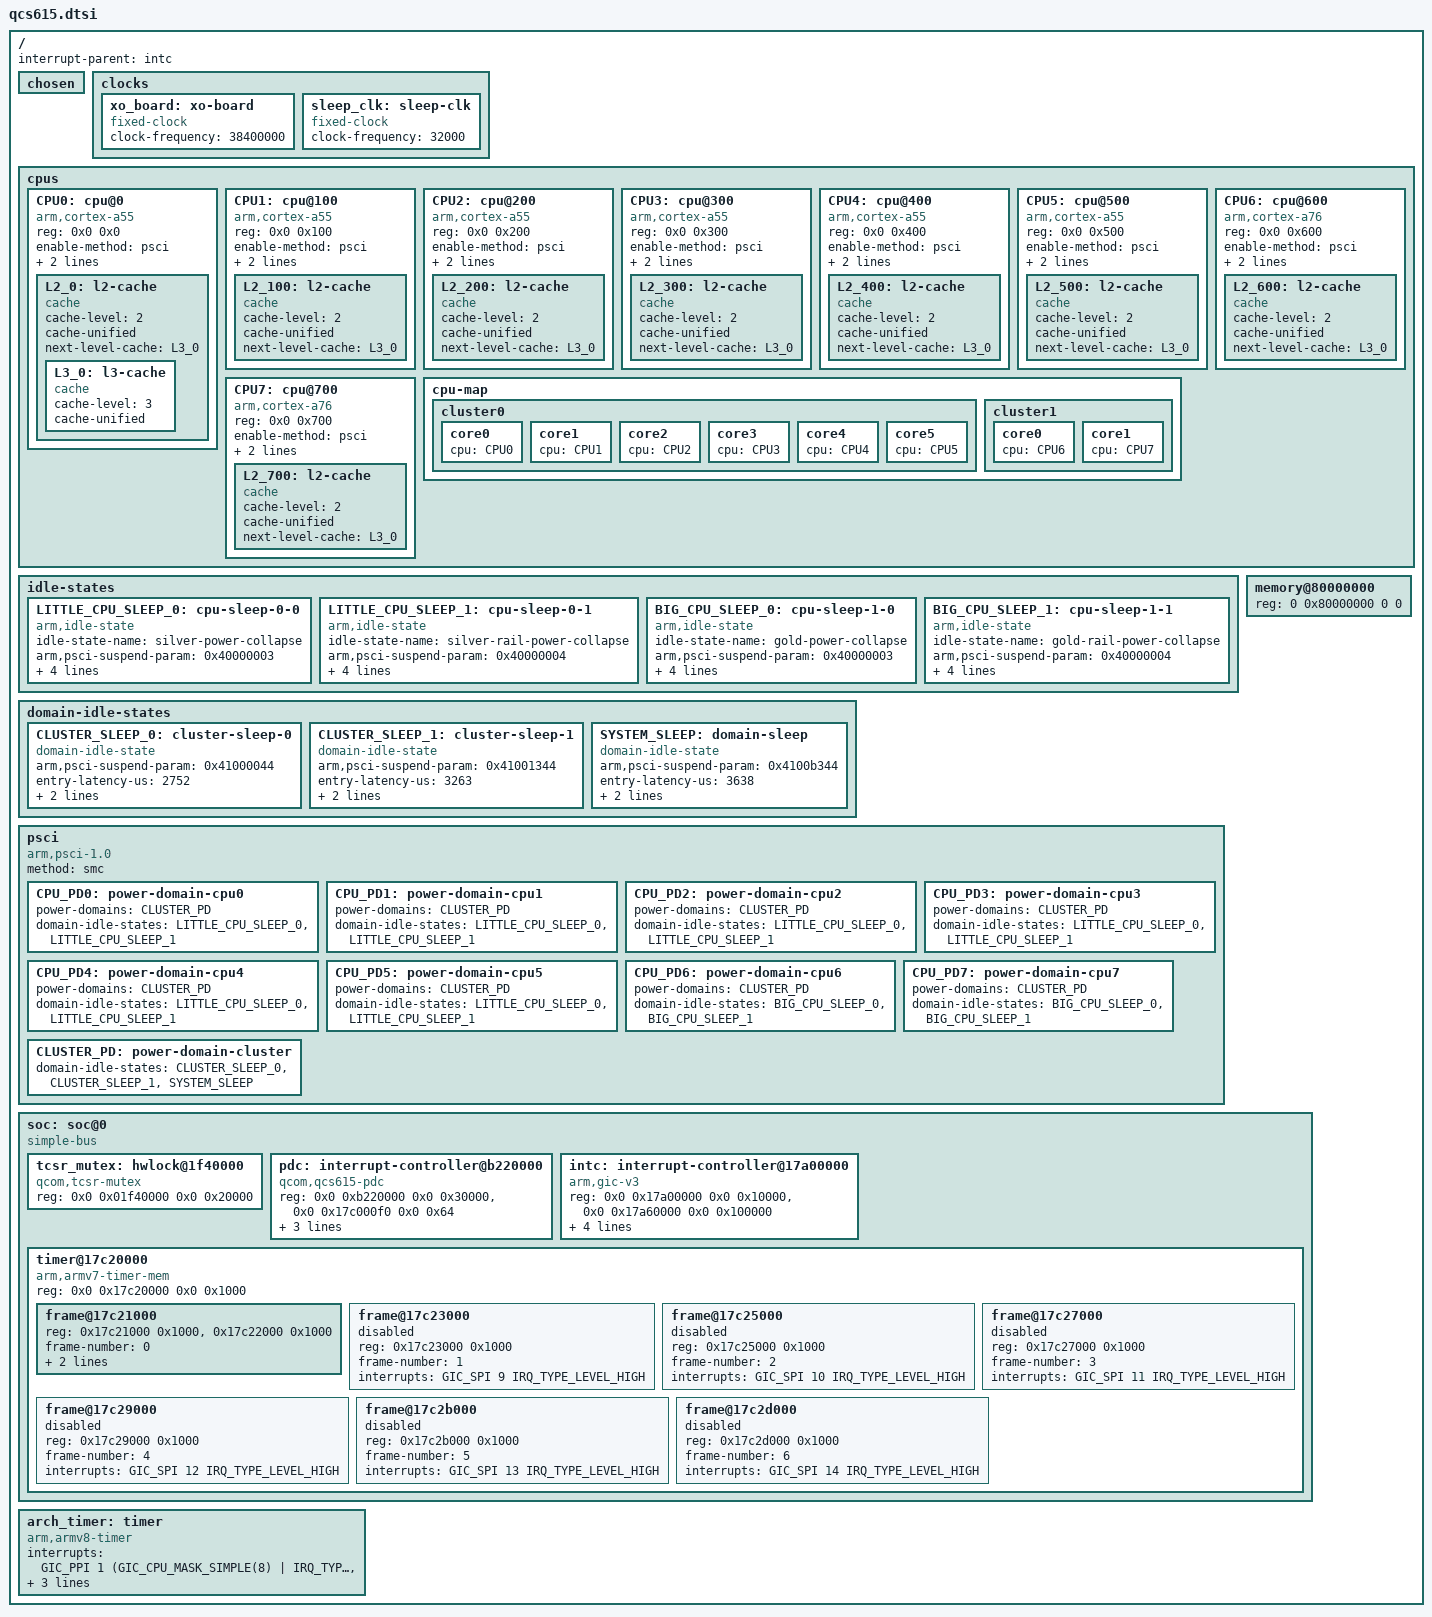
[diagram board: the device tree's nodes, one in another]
// SPDX-License-Identifier: BSD-3-Clause
/*
 * Copyright (c) 2024, Qualcomm Innovation Center, Inc. All rights reserved.
 */

#include <dt-bindings/interrupt-controller/arm-gic.h>

/ {
	interrupt-parent = <&intc>;

	#address-cells = <2>;
	#size-cells = <2>;

	chosen { };

	clocks {
		xo_board: xo-board {
			compatible = "fixed-clock";
			clock-frequency = <38400000>;
			#clock-cells = <0>;
		};

		sleep_clk: sleep-clk {
			compatible = "fixed-clock";
			clock-frequency = <32000>;
			#clock-cells = <0>;
		};
	};

	cpus {
		#address-cells = <2>;
		#size-cells = <0>;

		CPU0: cpu@0 {
			device_type = "cpu";
			compatible = "arm,cortex-a55";
			reg = <0x0 0x0>;
			enable-method = "psci";
			power-domains = <&CPU_PD0>;
			power-domain-names = "psci";
			next-level-cache = <&L2_0>;
			#cooling-cells = <2>;

			L2_0: l2-cache {
			      compatible = "cache";
			      cache-level = <2>;
			      cache-unified;
			      next-level-cache = <&L3_0>;

				L3_0: l3-cache {
				      compatible = "cache";
				      cache-level = <3>;
				      cache-unified;
				};
			};
		};

		CPU1: cpu@100 {
			device_type = "cpu";
			compatible = "arm,cortex-a55";
			reg = <0x0 0x100>;
			enable-method = "psci";
			power-domains = <&CPU_PD1>;
			power-domain-names = "psci";
			next-level-cache = <&L2_100>;

			L2_100: l2-cache {
			      compatible = "cache";
			      cache-level = <2>;
			      cache-unified;
			      next-level-cache = <&L3_0>;
			};
		};

		CPU2: cpu@200 {
			device_type = "cpu";
			compatible = "arm,cortex-a55";
			reg = <0x0 0x200>;
			enable-method = "psci";
			power-domains = <&CPU_PD2>;
			power-domain-names = "psci";
			next-level-cache = <&L2_200>;

			L2_200: l2-cache {
			      compatible = "cache";
			      cache-level = <2>;
			      cache-unified;
			      next-level-cache = <&L3_0>;
			};
		};

		CPU3: cpu@300 {
			device_type = "cpu";
			compatible = "arm,cortex-a55";
			reg = <0x0 0x300>;
			enable-method = "psci";
			power-domains = <&CPU_PD3>;
			power-domain-names = "psci";
			next-level-cache = <&L2_300>;

			L2_300: l2-cache {
			      compatible = "cache";
			      cache-level = <2>;
			      cache-unified;
			      next-level-cache = <&L3_0>;
			};
		};

		CPU4: cpu@400 {
			device_type = "cpu";
			compatible = "arm,cortex-a55";
			reg = <0x0 0x400>;
			enable-method = "psci";
			power-domains = <&CPU_PD4>;
			power-domain-names = "psci";
			next-level-cache = <&L2_400>;

			L2_400: l2-cache {
			      compatible = "cache";
			      cache-level = <2>;
			      cache-unified;
			      next-level-cache = <&L3_0>;
			};
		};

		CPU5: cpu@500 {
			device_type = "cpu";
			compatible = "arm,cortex-a55";
			reg = <0x0 0x500>;
			enable-method = "psci";
			power-domains = <&CPU_PD5>;
			power-domain-names = "psci";
			next-level-cache = <&L2_500>;

			L2_500: l2-cache {
			      compatible = "cache";
			      cache-level = <2>;
			      cache-unified;
			      next-level-cache = <&L3_0>;
			};
		};

		CPU6: cpu@600 {
			device_type = "cpu";
			compatible = "arm,cortex-a76";
			reg = <0x0 0x600>;
			enable-method = "psci";
			power-domains = <&CPU_PD6>;
			power-domain-names = "psci";
			next-level-cache = <&L2_600>;
			#cooling-cells = <2>;

			L2_600: l2-cache {
			      compatible = "cache";
			      cache-level = <2>;
			      cache-unified;
			      next-level-cache = <&L3_0>;
			};
		};

		CPU7: cpu@700 {
			device_type = "cpu";
			compatible = "arm,cortex-a76";
			reg = <0x0 0x700>;
			enable-method = "psci";
			power-domains = <&CPU_PD7>;
			power-domain-names = "psci";
			next-level-cache = <&L2_700>;

			L2_700: l2-cache {
			      compatible = "cache";
			      cache-level = <2>;
			      cache-unified;
			      next-level-cache = <&L3_0>;
			};
		};

		cpu-map {
			cluster0 {
				core0 {
					cpu = <&CPU0>;
				};

				core1 {
					cpu = <&CPU1>;
				};

				core2 {
					cpu = <&CPU2>;
				};

				core3 {
					cpu = <&CPU3>;
				};

				core4 {
					cpu = <&CPU4>;
				};

				core5 {
					cpu = <&CPU5>;
				};

			};

			cluster1 {
				core0 {
					cpu = <&CPU6>;
				};

				core1 {
					cpu = <&CPU7>;
				};
			};
		};
	};

	idle-states {
		LITTLE_CPU_SLEEP_0: cpu-sleep-0-0 {
			compatible = "arm,idle-state";
			idle-state-name = "silver-power-collapse";
			arm,psci-suspend-param = <0x40000003>;
			entry-latency-us = <549>;
			exit-latency-us = <901>;
			min-residency-us = <1774>;
			local-timer-stop;
		};

		LITTLE_CPU_SLEEP_1: cpu-sleep-0-1 {
			compatible = "arm,idle-state";
			idle-state-name = "silver-rail-power-collapse";
			arm,psci-suspend-param = <0x40000004>;
			entry-latency-us = <702>;
			exit-latency-us = <915>;
			min-residency-us = <4001>;
			local-timer-stop;
		};

		BIG_CPU_SLEEP_0: cpu-sleep-1-0 {
			compatible = "arm,idle-state";
			idle-state-name = "gold-power-collapse";
			arm,psci-suspend-param = <0x40000003>;
			entry-latency-us = <523>;
			exit-latency-us = <1244>;
			min-residency-us = <2207>;
			local-timer-stop;
		};

		BIG_CPU_SLEEP_1: cpu-sleep-1-1 {
			compatible = "arm,idle-state";
			idle-state-name = "gold-rail-power-collapse";
			arm,psci-suspend-param = <0x40000004>;
			entry-latency-us = <526>;
			exit-latency-us = <1854>;
			min-residency-us = <5555>;
			local-timer-stop;
		};
	};

	domain-idle-states {
		CLUSTER_SLEEP_0: cluster-sleep-0 {
			compatible = "domain-idle-state";
			arm,psci-suspend-param = <0x41000044>;
			entry-latency-us = <2752>;
			exit-latency-us = <3048>;
			min-residency-us = <6118>;
		};

		CLUSTER_SLEEP_1: cluster-sleep-1 {
			compatible = "domain-idle-state";
			arm,psci-suspend-param = <0x41001344>;
			entry-latency-us = <3263>;
			exit-latency-us = <4562>;
			min-residency-us = <8467>;
		};

		SYSTEM_SLEEP: domain-sleep {
			compatible = "domain-idle-state";
			arm,psci-suspend-param = <0x4100b344>;
			entry-latency-us = <3638>;
			exit-latency-us = <6562>;
			min-residency-us = <9826>;
		};
	};

	memory@80000000 {
		device_type = "memory";
		/* We expect the bootloader to fill in the size */
		reg = <0 0x80000000 0 0>;
	};

	psci {
		compatible = "arm,psci-1.0";
		method = "smc";

		CPU_PD0: power-domain-cpu0 {
			#power-domain-cells = <0>;
			power-domains = <&CLUSTER_PD>;
			domain-idle-states = <&LITTLE_CPU_SLEEP_0 &LITTLE_CPU_SLEEP_1>;
		};

		CPU_PD1: power-domain-cpu1 {
			#power-domain-cells = <0>;
			power-domains = <&CLUSTER_PD>;
			domain-idle-states = <&LITTLE_CPU_SLEEP_0 &LITTLE_CPU_SLEEP_1>;
		};

		CPU_PD2: power-domain-cpu2 {
			#power-domain-cells = <0>;
			power-domains = <&CLUSTER_PD>;
			domain-idle-states = <&LITTLE_CPU_SLEEP_0 &LITTLE_CPU_SLEEP_1>;
		};

		CPU_PD3: power-domain-cpu3 {
			#power-domain-cells = <0>;
			power-domains = <&CLUSTER_PD>;
			domain-idle-states = <&LITTLE_CPU_SLEEP_0 &LITTLE_CPU_SLEEP_1>;
		};

		CPU_PD4: power-domain-cpu4 {
			#power-domain-cells = <0>;
			power-domains = <&CLUSTER_PD>;
			domain-idle-states = <&LITTLE_CPU_SLEEP_0 &LITTLE_CPU_SLEEP_1>;
		};

		CPU_PD5: power-domain-cpu5 {
			#power-domain-cells = <0>;
			power-domains = <&CLUSTER_PD>;
			domain-idle-states = <&LITTLE_CPU_SLEEP_0 &LITTLE_CPU_SLEEP_1>;
		};

		CPU_PD6: power-domain-cpu6 {
			#power-domain-cells = <0>;
			power-domains = <&CLUSTER_PD>;
			domain-idle-states = <&BIG_CPU_SLEEP_0 &BIG_CPU_SLEEP_1>;
		};

		CPU_PD7: power-domain-cpu7 {
			#power-domain-cells = <0>;
			power-domains = <&CLUSTER_PD>;
			domain-idle-states = <&BIG_CPU_SLEEP_0 &BIG_CPU_SLEEP_1>;
		};

		CLUSTER_PD: power-domain-cluster {
			#power-domain-cells = <0>;
			domain-idle-states = <&CLUSTER_SLEEP_0 &CLUSTER_SLEEP_1 &SYSTEM_SLEEP>;
		};
	};

	soc: soc@0 {
		compatible = "simple-bus";
		ranges = <0 0 0 0 0x10 0>;
		#address-cells = <2>;
		#size-cells = <2>;

		tcsr_mutex: hwlock@1f40000 {
			compatible = "qcom,tcsr-mutex";
			reg = <0x0 0x01f40000 0x0 0x20000>;
			#hwlock-cells = <1>;
		};

		pdc: interrupt-controller@b220000 {
			compatible = "qcom,qcs615-pdc", "qcom,pdc";
			reg = <0x0 0xb220000 0x0 0x30000>,
			      <0x0 0x17c000f0 0x0 0x64>;
			qcom,pdc-ranges = <0 480 94>, <94 609 31>, <125 63 1>;
			interrupt-parent = <&intc>;
			#interrupt-cells = <2>;
			interrupt-controller;
		};

		intc: interrupt-controller@17a00000 {
			compatible = "arm,gic-v3";
			reg = <0x0 0x17a00000 0x0 0x10000>,     /* GICD */
			      <0x0 0x17a60000 0x0 0x100000>;    /* GICR * 8 */
			interrupts = <GIC_PPI 9 IRQ_TYPE_LEVEL_HIGH>;
			#interrupt-cells = <3>;
			interrupt-controller;
			#redistributor-regions = <1>;
			redistributor-stride = <0x0 0x20000>;
		};

		timer@17c20000 {
			compatible = "arm,armv7-timer-mem";
			reg = <0x0 0x17c20000 0x0 0x1000>;
			ranges = <0 0 0 0x20000000>;
			#address-cells = <1>;
			#size-cells = <1>;

			frame@17c21000 {
				reg = <0x17c21000 0x1000>,
				      <0x17c22000 0x1000>;
				frame-number = <0>;
				interrupts = <GIC_SPI 8 IRQ_TYPE_LEVEL_HIGH>,
					     <GIC_SPI 6 IRQ_TYPE_LEVEL_HIGH>;
			};

			frame@17c23000 {
				reg = <0x17c23000 0x1000>;
				frame-number = <1>;
				interrupts = <GIC_SPI 9 IRQ_TYPE_LEVEL_HIGH>;
				status = "disabled";
			};

			frame@17c25000 {
				reg = <0x17c25000 0x1000>;
				frame-number = <2>;
				interrupts = <GIC_SPI 10 IRQ_TYPE_LEVEL_HIGH>;
				status = "disabled";
			};

			frame@17c27000 {
				reg = <0x17c27000 0x1000>;
				frame-number = <3>;
				interrupts = <GIC_SPI 11 IRQ_TYPE_LEVEL_HIGH>;
				status = "disabled";
			};

			frame@17c29000 {
				reg = <0x17c29000 0x1000>;
				frame-number = <4>;
				interrupts = <GIC_SPI 12 IRQ_TYPE_LEVEL_HIGH>;
				status = "disabled";
			};

			frame@17c2b000 {
				reg = <0x17c2b000 0x1000>;
				frame-number = <5>;
				interrupts = <GIC_SPI 13 IRQ_TYPE_LEVEL_HIGH>;
				status = "disabled";
			};

			frame@17c2d000 {
				reg = <0x17c2d000 0x1000>;
				frame-number = <6>;
				interrupts = <GIC_SPI 14 IRQ_TYPE_LEVEL_HIGH>;
				status = "disabled";
			};
		};
	};

	arch_timer: timer {
		compatible = "arm,armv8-timer";
		interrupts = <GIC_PPI 1 (GIC_CPU_MASK_SIMPLE(8) | IRQ_TYPE_LEVEL_LOW)>,
			     <GIC_PPI 2 (GIC_CPU_MASK_SIMPLE(8) | IRQ_TYPE_LEVEL_LOW)>,
			     <GIC_PPI 3 (GIC_CPU_MASK_SIMPLE(8) | IRQ_TYPE_LEVEL_LOW)>,
			     <GIC_PPI 0 (GIC_CPU_MASK_SIMPLE(8) | IRQ_TYPE_LEVEL_LOW)>;
	};
};
